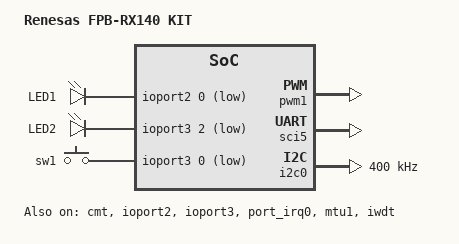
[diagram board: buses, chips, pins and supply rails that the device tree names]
/*
 * Copyright (c) 2025 Renesas Electronics Corporation
 *
 * SPDX-License-Identifier: Apache-2.0
 */

/dts-v1/;

#include <renesas/r5f51406.dtsi>
#include <dt-bindings/gpio/gpio.h>
#include "fpb_rx140-pinctrl.dtsi"
#include <zephyr/dt-bindings/input/input-event-codes.h>
#include <zephyr/dt-bindings/adc/adc.h>

/ {
	model = "Renesas FPB-RX140 KIT";
	compatible = "renesas,fpb_rx140";

	chosen {
		zephyr,sram = &sram0;
		zephyr,flash = &code_flash;
		zephyr,flash-controller = &flash;
		zephyr,console = &uart5;
		zephyr,shell-uart = &uart5;
	};

	leds {
		compatible = "gpio-leds";

		led1: led1 {
			gpios = <&ioport2 0 GPIO_ACTIVE_LOW>;
			label = "LED1";
		};

		led2: led2 {
			gpios = <&ioport3 2 GPIO_ACTIVE_LOW>;
			label = "LED2";
		};
	};

	buttons {
		compatible = "gpio-keys";

		sw1: button {
			label = "sw1";
			gpios = <&ioport3 0 (GPIO_PULL_UP | GPIO_ACTIVE_LOW)>;
			zephyr,code = <INPUT_KEY_0>;
		};
	};

	aliases {
		led0 = &led1;
		led1 = &led2;
		sw0 = &sw1;
		watchdog0 = &iwdt;
	};
};

&subclk {
	status = "okay";
};

&pclkblock {
	clocks = <&hoco>;
};

&cmt {
	clock-frequency = <3000000>;
	status = "okay";
};

&ioport2 {
	status = "okay";
};

&ioport3 {
	status = "okay";
};

&port_irq0 {
	status = "okay";
};

&mtu1 {
	status = "okay";
	pinctrl-0 = <&pwm1_default>;
	pinctrl-names = "default";

	pwm1: pwm {
		status = "okay";
	};
};

&sci5 {
	pinctrl-0 = <&sci5_default>;
	pinctrl-names = "default";
	status = "okay";

	uart5: uart {
		current-speed = <115200>;
		status = "okay";
	};
};

&rspi0 {
	pinctrl-0 = <&rspi0_default>;
	pinctrl-names = "default";
	ssl-assert = <0>;
};

&i2c0 {
	pinctrl-0 = <&i2c0_default>;
	pinctrl-names = "default";
	clock-frequency = <DT_FREQ_K(400)>;
	status = "okay";
};

&data_flash {
	partitions {
		compatible = "fixed-partitions";
		#address-cells = <1>;
		#size-cells = <1>;
		ranges;

		storage_partition: partition@0 {
			label = "storage";
			reg = <0x0 DT_SIZE_K(8)>;
		};
	};
};

&iwdt {
	window-start = <0x3000>;
	window-end = <0x0300>;
	status = "okay";
};
